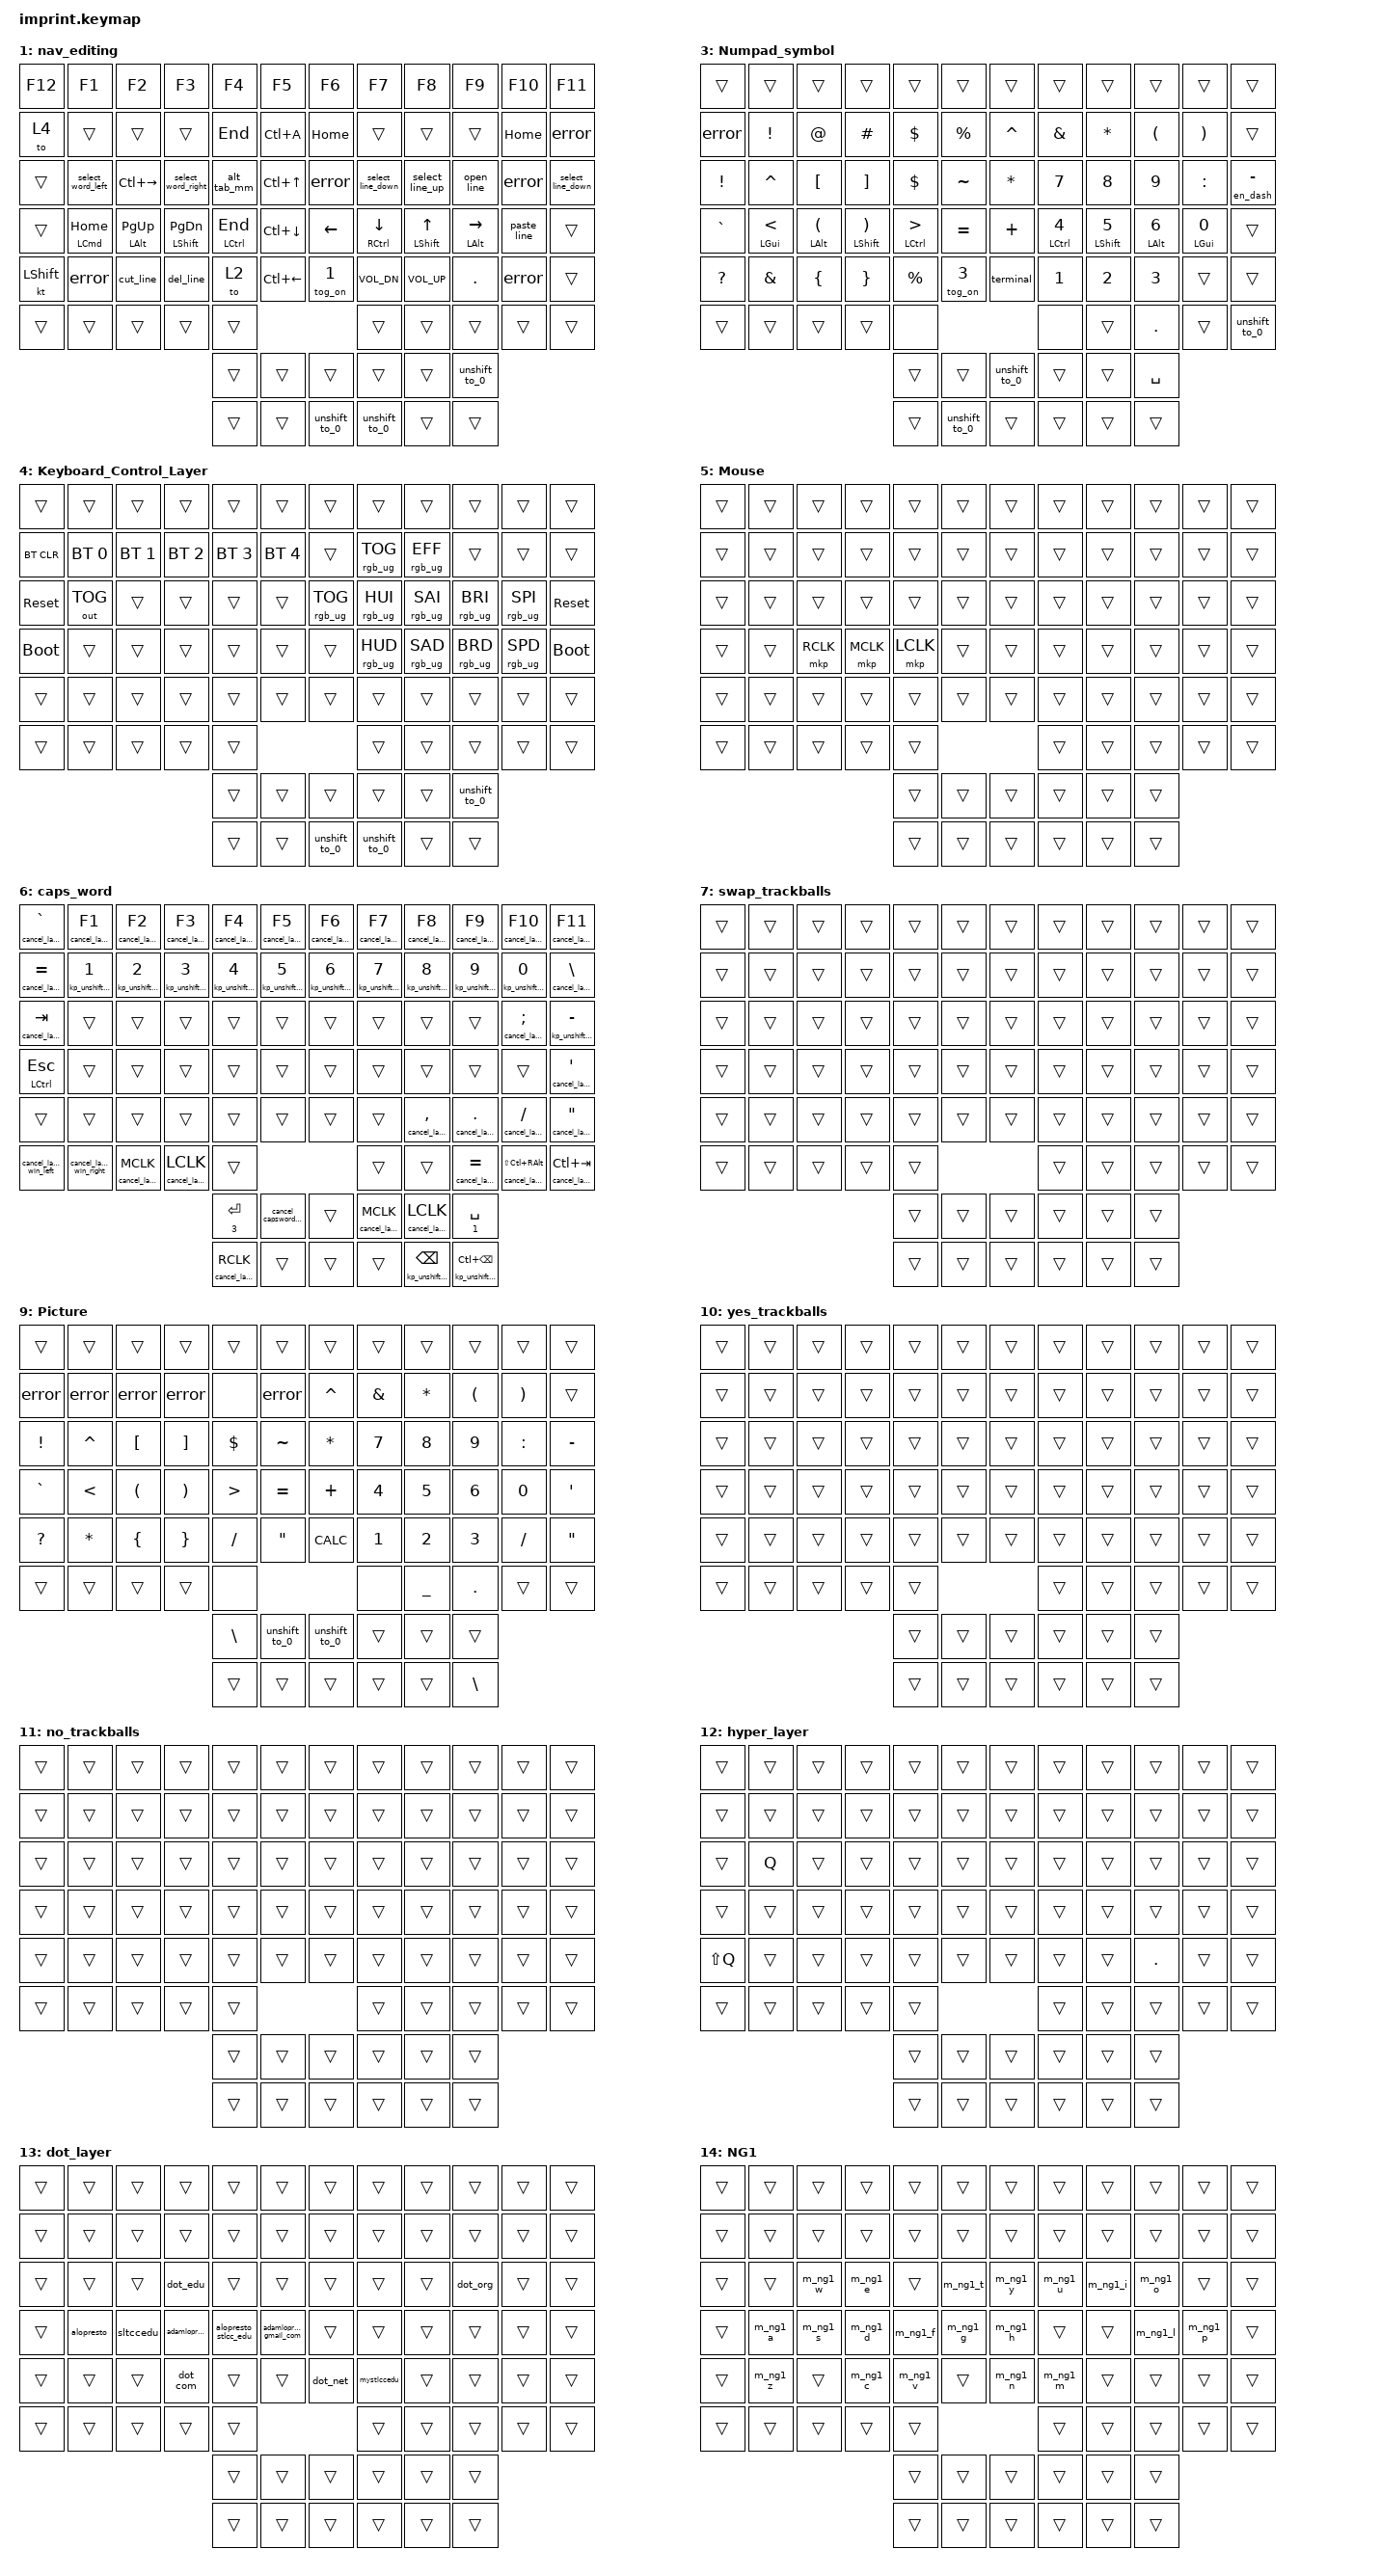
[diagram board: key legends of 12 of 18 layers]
#include <input/processors.dtsi>
#include <zephyr/dt-bindings/input/input-event-codes.h>
#include <dt-bindings/zmk/input_transform.h>
#include <behaviors.dtsi>
#include <dt-bindings/zmk/bt.h>
#include <dt-bindings/zmk/keys.h>
#include <dt-bindings/zmk/outputs.h>
#include <dt-bindings/zmk/pointing.h>
#include <dt-bindings/zmk/rgb.h>

&sk {
    quick-release;
    release-after-ms = <2000>;
};

/ {
    chosen { zmk,physical_layout = &physical_layout_imprint_function_row_full_bottom_row; };

    layer_listeners {
        compatible = "zmk,layer-listeners";

        cancel_mouse_scroll {
            layers = <11>;
            bindings = <&tog_off 10 &none>;
        };

        hyper_with_layer {
            layers = <12>;
            bindings = <&kt_on K_APP &kt_off K_APP>;
        };
    };

    behaviors {
        shift_dance: shift_dance {
            compatible = "zmk,behavior-tap-dance";
            label = "SHIFT_DANCE";
            #binding-cells = <0>;
            bindings = <&sticky_shift_cancel>, <&caps_layer>;
        };

        kt_off: key_toggle_off_only {
            compatible = "zmk,behavior-key-toggle";
            #binding-cells = <1>;
            display-name = "Key Toggle Off";
            toggle-mode = "off";
        };

        mo_to_blue: behavior_mo_to_blue {
            compatible = "zmk,behavior-hold-tap";
            label = "RGB blue, Hold for mo, tap for to layer";
            bindings = <&rgb_layer_mo_blue>, <&rgb_layer_to_blue>;

            #binding-cells = <2>;
            tapping-term-ms = <200>;
            hold-while-undecided;
        };

        hml: homerow_mod_left {
            compatible = "zmk,behavior-hold-tap";
            label = "Homerow mod left";
            bindings = <&kp>, <&kp>;

            #binding-cells = <2>;
            flavor = "balanced";
            tapping-term-ms = <280>;
            quick-tap-ms = <175>;
            require-prior-idle-ms = <250>;
            hold-trigger-on-release;
            hold-trigger-key-positions = <70 71 72 78 77 76 65 73 74 75 79 80 81 6 7 8 9 10 11 18 19 20 21 22 23 30 31 32 33 34 35 42 43 44 45 46 47 54 55 56 57 58 59 65 66 67 68 69>;
        };

        hmr: homerow_mod_right {
            compatible = "zmk,behavior-hold-tap";
            label = "homerow mod right";
            bindings = <&kp>, <&kp>;

            #binding-cells = <2>;
            flavor = "balanced";
            tapping-term-ms = <280>;
            quick-tap-ms = <175>;
            require-prior-idle-ms = <250>;
            hold-trigger-on-release;
            hold-trigger-key-positions = <0 1 2 3 4 5 12 13 14 15 16 17 24 25 26 27 28 29 36 37 38 39 40 41 48 49 50 51 52 53 60 61 62 63 64 70 71 72 73 74 76 77 78 79 80 75 81>;
        };

        hml_new_sentence: homerow_mod_left_ns {
            compatible = "zmk,behavior-hold-tap";
            label = "Homerow mod left ns";
            bindings = <&cancel_layer_kp>, <&sentence_start_kp>;

            #binding-cells = <2>;
            flavor = "balanced";
            tapping-term-ms = <280>;
            quick-tap-ms = <175>;
            require-prior-idle-ms = <250>;
            hold-trigger-on-release;
            hold-trigger-key-positions = <70 71 72 78 77 76 65 73 74 75 79 80 81 6 7 8 9 10 11 18 19 20 21 22 23 30 31 32 33 34 35 42 43 44 45 46 47 54 55 56 57 58 59 65 66 67 68 69>;
        };

        hmr_new_sentence: homerow_mod_right_ns {
            compatible = "zmk,behavior-hold-tap";
            label = "homerow mod right ns";
            bindings = <&cancel_layer_kp>, <&sentence_start_kp>;

            #binding-cells = <2>;
            flavor = "balanced";
            tapping-term-ms = <280>;
            quick-tap-ms = <175>;
            require-prior-idle-ms = <250>;
            hold-trigger-on-release;
            hold-trigger-key-positions = <0 1 2 3 4 5 12 13 14 15 16 17 24 25 26 27 28 29 36 37 38 39 40 41 48 49 50 51 52 53 60 61 62 63 64 70 71 72 73 74 76 77 78 79 80 75 81>;
        };

        tog_on: tog_on {
            compatible = "zmk,behavior-toggle-layer";
            label = "Turn on layer";
            #binding-cells = <1>;

            // locking;
        };

        hyper_tapdance: hyper_tapdance {
            compatible = "zmk,behavior-tap-dance";
            label = "HYPER_TAPDANCE";
            #binding-cells = <0>;
            bindings = <&sl 12>, <&kp F14>;
        };

        win_left: win_left {
            compatible = "zmk,behavior-mod-morph";
            label = "WIN_LEFT";
            bindings = <&kp LS(LG(LEFT))>, <&kp LG(LEFT)>;

            #binding-cells = <0>;
            mods = <(MOD_LCTL|MOD_LSFT|MOD_RCTL|MOD_RSFT)>;
            keep-mods = <(MOD_LCTL|MOD_RCTL)>;
        };

        win_right: win_right {
            compatible = "zmk,behavior-mod-morph";
            label = "WIN_RIGHT";
            bindings = <&kp LG(LS(RIGHT))>, <&kp LG(RIGHT)>;

            #binding-cells = <0>;
            mods = <(MOD_LCTL|MOD_LSFT|MOD_RSFT|MOD_RCTL)>;
            keep-mods = <(MOD_LCTL|MOD_RCTL)>;
        };

        ctrl_esc: ctrl_esc {
            compatible = "zmk,behavior-hold-tap";
            label = "CTRL_ESC";
            bindings = <&kp>, <&cancel_layer_kp>;

            #binding-cells = <2>;
            tapping-term-ms = <250>;
        };

        kt_on: kt_on {
            compatible = "zmk,behavior-key-toggle";
            #binding-cells = <1>;
            display-name = "Key Toggle Off";
            toggle-mode = "on";
            label = "KT_ON";
        };

        sticky_shift_cancel: sticky_shift_cancel {
            compatible = "zmk,behavior-mod-morph";
            label = "STICKY_SHIFT_CANCEL";
            bindings = <&sk LSHIFT>, <&kp K_CANCEL>;

            #binding-cells = <0>;
            mods = <(MOD_LSFT|MOD_RSFT)>;
        };

        tog_off: tog_off {
            compatible = "zmk,behavior-toggle-layer";
            label = "Toggle layer off";
            #binding-cells = <1>;
            toggle-mode = "off";

            // locking;
        };

        open_line: open_line {
            compatible = "zmk,behavior-mod-morph";
            label = "OPEN_LINE";
            bindings = <&open_line_below>, <&open_line_above>;

            #binding-cells = <0>;
            mods = <(MOD_LSFT|MOD_RSFT|MOD_LCTL|MOD_LALT|MOD_LGUI|MOD_RCTL|MOD_RGUI|MOD_RALT)>;
        };

        paste_line: paste_line {
            compatible = "zmk,behavior-mod-morph";
            label = "PASTE_LINE";
            bindings = <&paste_line_below>, <&paste_line_above>;

            #binding-cells = <0>;
            mods = <(MOD_LCTL|MOD_LSFT|MOD_LALT|MOD_LGUI|MOD_RSFT|MOD_RGUI|MOD_RCTL)>;
        };

        alt_tab_mm: alt_tab_mm {
            compatible = "zmk,behavior-mod-morph";
            label = "ALT_TAB_MM";
            bindings = <&alt_tab>, <&kp TAB>;

            #binding-cells = <0>;
            mods = <(MOD_LALT)>;
            keep-mods = <(MOD_LALT|MOD_LSFT)>;
        };

        hyphen_emdash: hyphen_emdash {
            compatible = "zmk,behavior-hold-tap";
            label = "HYPHEN_EMDASH";
            bindings = <&em_dash>, <&always_hyphen>;

            #binding-cells = <2>;
            tapping-term-ms = <150>;
            flavor = "tap-preferred";
            quick-tap-ms = <250>;
            require-prior-idle-ms = <0>;
            hold-trigger-key-positions = <64>;
        };

        hyphen_endash: hyphen_endash {
            compatible = "zmk,behavior-hold-tap";
            label = "HYPHEN_ENDASH";
            bindings = <&en_dash>, <&kp>;

            #binding-cells = <2>;
            tapping-term-ms = <150>;
            flavor = "tap-preferred";
            quick-tap-ms = <250>;
            require-prior-idle-ms = <0>;
            hold-trigger-key-positions = <64>;
        };

        rgb_layer_tap_enter: rgb_layer_tap_enter {
            compatible = "zmk,behavior-hold-tap";
            label = "RGB_LAYER_TAP_ENTER";
            bindings = <&rgb_layer_mo_blue>, <&cancel_layer_kp>;

            #binding-cells = <2>;
            tapping-term-ms = <500>;
            flavor = "hold-preferred";
            require-prior-idle-ms = <0>;
            quick-tap-ms = <200>;
            hold-while-undecided;
        };

        single_quote_ht: single_quote_ht {
            compatible = "zmk,behavior-hold-tap";
            label = "SINGLE_QUOTE_HT";
            bindings = <&single_quotes_pair>, <&kp>;

            #binding-cells = <2>;
            tapping-term-ms = <150>;
            flavor = "tap-preferred";
            quick-tap-ms = <250>;
            require-prior-idle-ms = <0>;
            hold-trigger-key-positions = <70>;
        };

        double_quote_ht: double_quote_ht {
            compatible = "zmk,behavior-hold-tap";
            label = "DOUBLE_QUOTE_HT";
            bindings = <&double_quotes_pair>, <&kp>;

            #binding-cells = <2>;
            tapping-term-ms = <150>;
            flavor = "tap-preferred";
            quick-tap-ms = <250>;
            require-prior-idle-ms = <0>;
            hold-trigger-key-positions = <64>;
        };

        lazy_sk: lazy_sk {
            compatible = "zmk,behavior-sticky-key";
            label = "LAZY_SK";
            bindings = <&kp>;
            #binding-cells = <1>;
            release-after-ms = <2000>;
            lazy;
            quick-release;
        };

        center_mm: center_mm {
            compatible = "zmk,behavior-mod-morph";
            label = "CENTER_MM";
            bindings = <&none>, <&kp F13>;

            #binding-cells = <0>;
            mods = <(MOD_LALT)>;
        };

        hmr_mouse: hmr_mouse {
            compatible = "zmk,behavior-hold-tap";
            label = "hmr_mouse";
            bindings = <&kp>, <&cancel_layer_kp>;

            #binding-cells = <2>;
            flavor = "balanced";
            tapping-term-ms = <280>;
            quick-tap-ms = <175>;
            require-prior-idle-ms = <250>;
            hold-trigger-on-release;
            hold-trigger-key-positions = <0 1 2 3 4 5 12 13 14 15 16 17 24 25 26 27 28 29 36 37 38 39 40 41 48 49 50 51 52 53 60 61 62 63 64 70 71 72 73 74 76 77 78 79 80 75 81>;
        };

        cancel_layer_win_left: cancel_layer_win_left {
            compatible = "zmk,behavior-mod-morph";
            label = "CANCEL_LAYER_WIN_LEFT";
            bindings =
                <&cancel_layer_kp LS(LG(LEFT))>,
                <&cancel_layer_kp LG(LEFT)>;

            #binding-cells = <0>;
            mods = <(MOD_LCTL|MOD_LSFT|MOD_RCTL|MOD_RSFT)>;
            keep-mods = <(MOD_LCTL|MOD_RCTL)>;
        };

        cancel_layer_win_right: cancel_layer_win_right {
            compatible = "zmk,behavior-mod-morph";
            label = "CANCEL_LAYER_WIN_RIGHT";
            bindings =
                <&cancel_layer_kp LG(LS(RIGHT))>,
                <&cancel_layer_kp LG(RIGHT)>;

            #binding-cells = <0>;
            mods = <(MOD_LCTL|MOD_LSFT|MOD_RSFT|MOD_RCTL)>;
            keep-mods = <(MOD_LCTL|MOD_RCTL)>;
        };

        rgb_layer_tap_space: rgb_layer_tap_space {
            compatible = "zmk,behavior-hold-tap";
            label = "RGB_LAYER_TAP_SPACE";
            bindings = <&rgb_layer_mo_blue>, <&cancel_layer_kp>;

            #binding-cells = <2>;
            tapping-term-ms = <500>;
            flavor = "balanced";
            require-prior-idle-ms = <200>;
            quick-tap-ms = <200>;
            hold-while-undecided;
        };

        terminal: terminal {
            compatible = "zmk,behavior-tap-dance";
            label = "TERMINAL";
            #binding-cells = <0>;
            bindings = <&kp LG(GRAVE)>, <&dollar_under>, <&dollar_under_equal>;
        };

        dot: dot {
            compatible = "zmk,behavior-hold-tap";
            label = "DOT";
            bindings = <&mo>, <&kp>;

            #binding-cells = <2>;
            flavor = "balanced";
            tapping-term-ms = <280>;
            quick-tap-ms = <175>;
            require-prior-idle-ms = <250>;
            hold-trigger-key-positions = <38 41 27 51 54 33 32 58 37 39 40>;
        };

        always_hyphen: always_hyphen {
            compatible = "zmk,behavior-mod-morph";
            label = "ALWAYS_HYPHEN";
            bindings = <&kp MINUS>, <&kp_unshifted MINUS>;

            #binding-cells = <0>;
            mods = <(MOD_LSFT|MOD_RSFT)>;
        };

        qu_mm: qu_mm {
            compatible = "zmk,behavior-mod-morph";
            label = "QU_MM";
            bindings = <&qu_macro>, <&qu_caps_macro>;

            #binding-cells = <0>;
            mods = <(MOD_LSFT)>;
        };

        zip_auto_mouse: zip_auto_mouse {
            compatible = "zmk,input-processor-temp-layer";
            #input-processor-cells = <2>;
            require-prior-idle-ms = <1000>;
            excluded-positions = <64>;
        };

        zip_scroll_to_vol: zip_scroll_to_vol {
            compatible = "zmk,input-processor-keybind";
            #input-processor-cells = <0>;
            bindings = <&none>, <&none>, <&kp C_VOL_UP>, <&kp C_VOL_DN>;
        };

        zip_keybind_keys: zip_keybind_keys {
            compatible = "zmk,input-processor-keybind";
            #input-processor-cells = <0>;
            track_remainders;
            bindings = <&kp RIGHT>, <&kp LEFT>, <&kp UP>, <&kp DOWN>;

            tick = <15>;
            wait-ms = <0>;
            tap-ms = <10>;

            // mode = <1>
            // threshold = <10>
            // max_threshold = <200>
            // max_pending_activations = <10>
        };

        // Scoped momentary layer that turns off continuation layers 15 & 17 on thumb release

        ng_hold: ng_hold {
            compatible = "zmk,behavior-macro-one-param";
            label = "NG_HOLD";
            #binding-cells = <1>;
            wait-ms = <0>;
            tap-ms = <0>;
            bindings =
                <&macro_param_1to1>,
                <&macro_press>,
                <&mo MACRO_PLACEHOLDER>,
                <&macro_pause_for_release>,
                <&macro_param_1to1>,
                <&macro_release>,
                <&mo MACRO_PLACEHOLDER>,
                <&macro_tap>,
                <&tog_off 15>,
                <&macro_tap>,
                <&tog_off 17>;
        };

        // Hold-tap for thumb positions 80 and 81

        ng_lt: ng_lt {
            compatible = "zmk,behavior-hold-tap";
            label = "NG_LT";
            bindings = <&ng_hold>, <&kp>;

            #binding-cells = <2>;
            flavor = "hold-preferred";
            tapping-term-ms = <200>;
            quick-tap-ms = <175>;
        };

        alt_f4: alt_f4 {
            compatible = "zmk,behavior-mod-morph";
            label = "ALT_F4";
            bindings = <&kp LA(F4)>, <&kp F4>;

            #binding-cells = <0>;
            mods = <(MOD_LCTL|MOD_LSFT|MOD_LALT|MOD_LGUI)>;
            keep-mods = <(MOD_LCTL|MOD_LSFT|MOD_LGUI)>;
        };

        // zip_auto_scroll: zip_auto_scroll {
        //     compatible = "zmk,input-processor-temp-layer";
        //     #input-processor-cells = <2>;
        //     require-prior-idle-ms = <1000>;
        //     excluded-positions = <64>;
        // };
    };

    macros {
        select_word_left: select_word_left {
            compatible = "zmk,behavior-macro";
            #binding-cells = <0>;
            bindings = <&tog_on 2 &kp LC(LEFT) &kp LC(RIGHT) &kp LS(LC(LEFT))>;
            label = "SELECT_WORD_LEFT";
            wait-ms = <0>;
            tap-ms = <0>;
        };

        select_word_right: select_word_right {
            compatible = "zmk,behavior-macro";
            #binding-cells = <0>;
            bindings = <&tog_on 2 &kp LC(RIGHT) &kp LC(LEFT) &kp LS(LC(RIGHT))>;
            label = "SELECT_WORD_RIGHT";
            wait-ms = <0>;
            tap-ms = <0>;
        };

        select_line_down: select_line_down {
            compatible = "zmk,behavior-macro";
            #binding-cells = <0>;
            bindings = <&tog_on 2 &kp HOME &kp LS(END)>;
            label = "SELECT_LINE";
            wait-ms = <0>;
            tap-ms = <0>;
        };

        select_line_up: select_line_up {
            compatible = "zmk,behavior-macro";
            #binding-cells = <0>;
            bindings = <&tog_on 2 &kp END &kp LS(HOME)>;
            label = "SELECT_LINE_UP";
            wait-ms = <0>;
            tap-ms = <0>;
        };

        unshift_to_0: unshift_to_0 {
            compatible = "zmk,behavior-macro";
            #binding-cells = <0>;
            bindings = <&kt_off LSHIFT &rgb_ug RGB_OFF &rgb_ug RGB_COLOR_HSB(0,0,1) &kt_off LALT &tog_off 1 &tog_off 2 &tog_off 3 &tog_off 4 &tog_off 5 &tog_off 6 &tog_off 7 &tog_off 8 &tog_off 9 &tog_off 10 &tog_off 14 &tog_off 15 &tog_off 16 &tog_off 17>;
            label = "UNSHIFT_TO_0";
            wait-ms = <0>;
            tap-ms = <0>;
        };

        rgb_layer_to_blue: rgb_layer_to {
            compatible = "zmk,behavior-macro-one-param";
            #binding-cells = <1>;
            bindings = <&macro_param_1to1 &to MACRO_PLACEHOLDER &rgb_ug RGB_COLOR_HSB(223,100,1) &rgb_ug RGB_ON>;
            label = "RGB_LAYER_TOG";
            wait-ms = <0>;
            tap-ms = <0>;
        };

        rgb_layer_mo_blue: rgb_layer_mo {
            compatible = "zmk,behavior-macro-one-param";
            #binding-cells = <1>;
            bindings =
                <&unshift_to_0>,
                <&macro_press>,
                <&macro_param_1to1 &mo MACRO_PLACEHOLDER &rgb_ug RGB_COLOR_HSB(199,100,1) &rgb_ug RGB_ON>,
                <&macro_pause_for_release>,
                <&macro_release>,
                <&macro_param_1to1 &mo MACRO_PLACEHOLDER>,
                <&macro_tap>,
                <&rgb_ug RGB_OFF &rgb_ug RGB_COLOR_HSB(0,0,1) &center_mm &kt_off LEFT_ALT &tog_off 2>;

            label = "RGB_LAYER_MO";
            wait-ms = <0>;
            tap-ms = <0>;
        };

        rgb_layer_to_green: rgb_layer_tog_green {
            compatible = "zmk,behavior-macro-one-param";
            #binding-cells = <1>;
            bindings = <&macro_param_1to1 &to MACRO_PLACEHOLDER &rgb_ug RGB_COLOR_HSB(116,100,1) &rgb_ug RGB_ON>;
            label = "RGB_LAYER_TOG_GREEN";
            wait-ms = <0>;
            tap-ms = <0>;
        };

        rgb_layer_to_yellow: rgb_layer_to_yellow {
            compatible = "zmk,behavior-macro-one-param";
            #binding-cells = <1>;
            bindings = <&macro_param_1to1 &to MACRO_PLACEHOLDER &rgb_ug RGB_COLOR_HSB(61,85,1) &rgb_ug RGB_ON>;
            label = "RGB_LAYER_TO_YELLOW";
            wait-ms = <0>;
            tap-ms = <0>;
        };

        hyper_kp: hyper_kp {
            compatible = "zmk,behavior-macro-one-param";
            #binding-cells = <1>;
            bindings = <&sk K_APP &macro_param_1to1 &kp MACRO_PLACEHOLDER>;
            label = "HYPER_KP";
        };

        kp_unshifted: kp_unshifted {
            compatible = "zmk,behavior-macro-one-param";
            #binding-cells = <1>;
            bindings = <&kt_off LSHIFT &macro_param_1to1 &kp MACRO_PLACEHOLDER &kt LSHIFT>;
            label = "KP_UNSHIFTED";
            wait-ms = <0>;
            tap-ms = <0>;
        };

        cancel_layer_kp: cancel_layer_kp {
            compatible = "zmk,behavior-macro-one-param";
            #binding-cells = <1>;
            bindings =
                <&unshift_to_0>,
                <&macro_press>,
                <&macro_param_1to1 &kp MACRO_PLACEHOLDER>,
                <&macro_pause_for_release>,
                <&macro_release>,
                <&macro_param_1to1 &kp MACRO_PLACEHOLDER>;

            label = "CANCEL_LAYER_KP";
            wait-ms = <0>;
            tap-ms = <0>;
        };

        caps_layer: caps_layer {
            compatible = "zmk,behavior-macro";
            #binding-cells = <0>;
            bindings = <&to 6 &kt LSHIFT &rgb_ug RGB_COLOR_HSB(0,0,1) &rgb_ug RGB_ON>;
            label = "CAPS_LAYER";
            wait-ms = <0>;
            tap-ms = <0>;
        };

        cancel_layer_mkp: cancel_capsword_mp {
            compatible = "zmk,behavior-macro-one-param";
            #binding-cells = <1>;
            bindings =
                <&unshift_to_0>,
                <&macro_press>,
                <&macro_param_1to1 &mkp MACRO_PLACEHOLDER>,
                <&macro_pause_for_release>,
                <&macro_release>,
                <&macro_param_1to1 &mkp MACRO_PLACEHOLDER>;

            label = "CANCEL_CAPSWORD_MP";
            wait-ms = <0>;
            tap-ms = <0>;
        };

        cancel_capsword_shift: cancel_capsword_shift {
            compatible = "zmk,behavior-macro";
            #binding-cells = <0>;
            bindings =
                <&unshift_to_0 &kt LSHIFT>,
                <&macro_pause_for_release>,
                <&kt LEFT_SHIFT>;

            label = "CANCEL_CAPSWORD_SHIFT";
        };

        error: error {
            compatible = "zmk,behavior-macro";
            #binding-cells = <0>;
            bindings =
                <&kp F14 &rgb_ug RGB_TOG>,
                <&macro_wait_time 125>,
                <&rgb_ug RGB_TOG>;

            label = "ERROR";
        };

        rgb_layer_mo_green: rgb_layer_mo_green {
            compatible = "zmk,behavior-macro-one-param";
            #binding-cells = <1>;
            bindings =
                <&unshift_to_0>,
                <&macro_press>,
                <&macro_param_1to1 &mo MACRO_PLACEHOLDER &rgb_ug RGB_COLOR_HSB(124,100,1) &rgb_ug RGB_ON>,
                <&macro_pause_for_release>,
                <&macro_release>,
                <&macro_param_1to1 &mo MACRO_PLACEHOLDER>,
                <&macro_tap>,
                <&rgb_ug RGB_OFF &rgb_ug RGB_COLOR_HSB(0,0,1)>;

            label = "RGB_LAYER_MO_GREEN";
            wait-ms = <0>;
            tap-ms = <0>;
        };

        drag_toggle: drag_toggle {
            compatible = "zmk,behavior-macro";
            #binding-cells = <0>;
            bindings = <&macro_release>, <&mkp MB1>, <&macro_press>, <&mkp MB1>;

            label = "DRAG_TOGGLE";
        };

        unclick_click: unclick_click {
            compatible = "zmk,behavior-macro";
            #binding-cells = <0>;
            bindings =
                <&macro_release>,
                <&mkp MB1>,
                <&macro_press>,
                <&mkp MB1>,
                <&macro_pause_for_release>,
                <&macro_release>,
                <&mkp MB1>;

            label = "UNCLICK_CLICK";
            wait-ms = <0>;
            tap-ms = <0>;
        };

        alt_tab: alt_tab {
            compatible = "zmk,behavior-macro";
            #binding-cells = <0>;
            bindings = <&kt_on LALT &kp TAB>;
            label = "ALT_TAB";
        };

        pair_macro: pair_macro {
            compatible = "zmk,behavior-macro-two-param";
            #binding-cells = <2>;
            bindings = <&macro_param_1to1 &kp MACRO_PLACEHOLDER &macro_param_2to1 &kp MACRO_PLACEHOLDER &kp LEFT>;
            label = "PAIR_MACRO";
        };

        error_kp: error_kp {
            compatible = "zmk,behavior-macro-one-param";
            #binding-cells = <1>;
            bindings = <&macro_param_1to1 &kp MACRO_PLACEHOLDER &error>;
            label = "ERROR_KP";
        };

        sentence_end: sentence_end {
            compatible = "zmk,behavior-macro-one-param";
            #binding-cells = <1>;
            bindings = <&kt_off LSHIFT &macro_param_1to1 &kp MACRO_PLACEHOLDER &tog_on 8 &rgb_ug RGB_COLOR_HSB(0,0,1) &rgb_ug RGB_ON>;
            label = "SENTENCE_END";
            wait-ms = <0>;
            tap-ms = <0>;
        };

        sentence_start_kp: sentence_start {
            compatible = "zmk,behavior-macro-one-param";
            #binding-cells = <1>;
            bindings =
                <&unshift_to_0 &kp SPACE>,
                <&macro_press>,
                <&macro_param_1to1 &kp MACRO_PLACEHOLDER>,
                <&macro_pause_for_release>,
                <&macro_release>,
                <&macro_param_1to1 &kp MACRO_PLACEHOLDER &unshift_to_0>;

            label = "Send space then kp";
            wait-ms = <0>;
            tap-ms = <0>;
        };

        cut_line: cut_line {
            compatible = "zmk,behavior-macro";
            #binding-cells = <0>;
            bindings = <&kp HOME &kp LS(END) &kp LC(X) &kp DELETE>;
            label = "CUT_LINE";
            wait-ms = <0>;
            tap-ms = <0>;
        };

        open_line_above: open_line_above {
            compatible = "zmk,behavior-macro";
            #binding-cells = <0>;
            bindings = <&kp HOME &kt_off LSHIFT &kp ENTER &kt_off LSHIFT &kp UP>;
            label = "OPEN_LINE_ABOVE";
            wait-ms = <0>;
            tap-ms = <0>;
        };

        open_line_below: open_line_below {
            compatible = "zmk,behavior-macro";
            #binding-cells = <0>;
            bindings = <&kp END &kp ENTER>;
            label = "OPEN_LINE_BELOW";
            wait-ms = <0>;
            tap-ms = <0>;
        };

        paste_line_above: paste_line_above {
            compatible = "zmk,behavior-macro";
            #binding-cells = <0>;
            bindings = <&kp HOME &kt_off LSHIFT &kp ENTER &kt_off LSHIFT &kp UP &kt_off LSHIFT &kp LC(V)>;
            label = "PASTE_LINE_ABOVE";
            wait-ms = <0>;
            tap-ms = <0>;
        };

        paste_line_below: paste_line_below {
            compatible = "zmk,behavior-macro";
            #binding-cells = <0>;
            bindings = <&kp END &kp ENTER &kp LC(V)>;
            label = "PASTE_LINE_BELOW";
            wait-ms = <0>;
            tap-ms = <0>;
        };

        paste_replace: paste_replace {
            compatible = "zmk,behavior-macro";
            #binding-cells = <0>;
            bindings =
                <&kt_off LSHIFT &kp LC(X) &kp LG(V)>,
                <&macro_wait_time 1000>,
                <&kp DOWN &kp ENTER>;

            label = "PASTE_REPLACE";
        };

        del_line: del_line {
            compatible = "zmk,behavior-macro";
            #binding-cells = <0>;
            bindings = <&kp HOME &kp LS(END) &kp DELETE &kp DELETE>;
            label = "DEL_LINE";
            wait-ms = <0>;
            tap-ms = <0>;
        };

        en_dash: en_dash {
            compatible = "zmk,behavior-macro";
            #binding-cells = <0>;
            bindings = <&kp LG(MINUS)>;
            label = "EN_DASH";
            wait-ms = <0>;
            tap-ms = <0>;
        };

        em_dash: em_dash {
            compatible = "zmk,behavior-macro";
            #binding-cells = <0>;
            bindings = <&kp LS(LG(MINUS))>;
            label = "EM_DASH";
            wait-ms = <0>;
            tap-ms = <0>;
        };

        double_quotes_pair: double_quotes_pair {
            compatible = "zmk,behavior-macro";
            #binding-cells = <0>;
            bindings = <&kp RA(GRAVE) &kp GRAVE &kp RA(SINGLE_QUOTE) &kp SINGLE_QUOTE &kp LEFT>;
            label = "DOUBLE_QUOTES_PAIR";
        };

        single_quotes_pair: single_quotes_pair {
            compatible = "zmk,behavior-macro";
            #binding-cells = <0>;
            bindings = <&kp RA(N6) &kp SINGLE_QUOTE &kp RA(N9) &kp SINGLE_QUOTE &kp LEFT>;
            label = "SINGLE_QUOTES_PAIR";
        };

        the_macro: the_macro {
            compatible = "zmk,behavior-macro";
            #binding-cells = <0>;
            bindings = <&kp T &kp H &kp E>;
            label = "THE_MACRO";
            tap-ms = <0>;
            wait-ms = <0>;
        };

        the_caps_macro: the_caps_macro {
            compatible = "zmk,behavior-macro";
            #binding-cells = <0>;
            bindings = <&kp LS(T) &kt_off LSHFT &kp H &kp E>;
            label = "THE_CAPS_MACRO";
            wait-ms = <0>;
            tap-ms = <0>;
        };

        sentence_start_the_macro: sentence_start_the_macro {
            compatible = "zmk,behavior-macro";
            #binding-cells = <0>;
            bindings = <&unshift_to_0 &kp SPACE &kp LS(T) &kp H &kp E>;
            label = "SENTENCE_START_THE_MACRO";
            wait-ms = <0>;
            tap-ms = <0>;
        };

        double_click: double_click {
            compatible = "zmk,behavior-macro-one-param";
            #binding-cells = <1>;
            bindings =
                <&unshift_to_0 &macro_param_1to1 &mkp MACRO_PLACEHOLDER>,
                <&macro_press>,
                <&macro_param_1to1 &mkp MACRO_PLACEHOLDER>,
                <&macro_pause_for_release>,
                <&macro_release>,
                <&macro_param_1to1 &mkp MACRO_PLACEHOLDER>;

            label = "DOUBLE_CLICK";
        };

        tion_macro: tion_macro {
            compatible = "zmk,behavior-macro";
            #binding-cells = <0>;
            bindings = <&kp T &kp I &kp O &kp N>;
            label = "TION_MACRO";
            wait-ms = <0>;
            tap-ms = <0>;
        };

        ing_macro: ing_macro {
            compatible = "zmk,behavior-macro";
            #binding-cells = <0>;
            bindings = <&kp I &kp N &kp G>;
            label = "ING_MACRO";
            wait-ms = <0>;
            tap-ms = <0>;
        };

        rgb_on: rgb_on {
            compatible = "zmk,behavior-macro";
            #binding-cells = <0>;
            bindings = <&rgb_ug RGB_COLOR_HSB(0,100,0) &rgb_ug RGB_ON>;
            label = "RGB_ON";
        };

        cancel_trackball_mkp: cancel_trackball_mkp {
            compatible = "zmk,behavior-macro-one-param";
            #binding-cells = <1>;
            bindings =
                <&macro_press>,
                <&macro_param_1to1 &mkp MACRO_PLACEHOLDER>,
                <&macro_pause_for_release>,
                <&macro_release>,
                <&macro_param_1to1 &mkp MACRO_PLACEHOLDER>,
                <&macro_tap>,
                <&tog_off 10 &sl 10>;

            label = "CANCEL_TRACKBALL_MKP";
            wait-ms = <0>;
            tap-ms = <0>;
        };

        ough_macro: ought_macro {
            compatible = "zmk,behavior-macro";
            #binding-cells = <0>;
            bindings = <&kp O &kp U &kp G &kp H>;
            label = "OUGHT_MACRO";
            wait-ms = <10>;
            tap-ms = <15>;
        };

        qu_macro: qu_macro {
            compatible = "zmk,behavior-macro";
            #binding-cells = <0>;
            bindings = <&kp Q &kp U>;
            label = "QU_MACRO";
            wait-ms = <0>;
            tap-ms = <0>;
        };

        qu_macro_sentence_start: qu_macro_sentence_start {
            compatible = "zmk,behavior-macro";
            #binding-cells = <0>;
            bindings = <&unshift_to_0 &kp SPACE &kp LS(Q) &kp U>;
            label = "QU_MACRO_SENTENCE_START";
            wait-ms = <0>;
            tap-ms = <0>;
        };

        hyper_hold: hyper_macro {
            compatible = "zmk,behavior-macro";
            #binding-cells = <0>;
            bindings =
                <&macro_press>,
                <&mo 12 &kp K_APP>,
                <&macro_pause_for_release>,
                <&macro_release>,
                <&mo 12 &kp K_APP>;

            label = "HYPER_MACRO";
            wait-ms = <0>;
            tap-ms = <0>;
        };

        surround: surround {
            compatible = "zmk,behavior-macro-two-param";
            #binding-cells = <2>;
            bindings = <&kp LC(X) &macro_param_1to1 &kp MACRO_PLACEHOLDER &kp LC(V) &macro_param_2to1 &kp MACRO_PLACEHOLDER>;
            label = "SURROUND";
        };

        dollar_under: dollar_under {
            compatible = "zmk,behavior-macro";
            #binding-cells = <0>;
            bindings = <&kp DLLR &kp UNDER &kp UNDER>;
            label = "DOLLAR_UNDER";
        };

        dollar_under_equal: dollar_under_equal {
            compatible = "zmk,behavior-macro";
            #binding-cells = <0>;
            bindings = <&kp DLLR &kp UNDER &kp UNDER &kp EQUAL>;
            label = "DOLLAR_UNDER_EQUAL";
        };

        thanks_macro: thanks_macro {
            compatible = "zmk,behavior-macro";
            #binding-cells = <0>;
            bindings = <&kp LS(T) &kp H &kp A &kp N &kp K &kp S &sentence_end EXCLAMATION>;
            label = "THANKS_MACRO";
            wait-ms = <0>;
            tap-ms = <0>;
        };

        and_macro: and_macro {
            compatible = "zmk,behavior-macro";
            #binding-cells = <0>;
            bindings = <&kp SPACE &kp A &kp N &kp D &kp SPACE>;
            label = "AND_MACRO";
            wait-ms = <0>;
            tap-ms = <0>;
        };

        dot_com: dot_com {
            compatible = "zmk,behavior-macro";
            #binding-cells = <0>;
            bindings = <&kp DOT &kp C &kp O &kp M>;
            label = "DOT_COM";
            wait-ms = <0>;
            tap-ms = <0>;
        };

        dot_net: dot_net {
            compatible = "zmk,behavior-macro";
            #binding-cells = <0>;
            bindings = <&kp DOT &kp N &kp E &kp T>;
            label = "DOT_NET";
            wait-ms = <0>;
            tap-ms = <0>;
        };

        dot_org: dot_org {
            compatible = "zmk,behavior-macro";
            #binding-cells = <0>;
            bindings = <&kp DOT &kp O &kp R &kp G>;
            label = "DOT_ORG";
            wait-ms = <0>;
            tap-ms = <0>;
        };

        dot_edu: dot_edu {
            compatible = "zmk,behavior-macro";
            #binding-cells = <0>;
            bindings = <&kp DOT &kp E &kp D &kp U>;
            label = "DOT_EDU";
            wait-ms = <0>;
            tap-ms = <0>;
        };

        alopresto_stlcc_edu: alopresto_stlcc_edu {
            compatible = "zmk,behavior-macro";
            #binding-cells = <0>;
            bindings = <&kp A &kp L &kp O &kp P &kp R &kp E &kp S &kp T &kp O &kp AT &kp S &kp T &kp L &kp C &kp C &kp DOT &kp E &kp D &kp U>;
            label = "ALOPRESTO_STLCC_EDU";
        };

        adamlopresto_gmail_com: adamlopresto_gmail_com {
            compatible = "zmk,behavior-macro";
            #binding-cells = <0>;
            bindings = <&kp A &kp D &kp A &kp M &kp L &kp O &kp P &kp R &kp E &kp S &kp T &kp O &kp AT &kp G &kp M &kp A &kp I &kp L &kp DOT &kp C &kp O &kp M>;
            label = "ADAMLOPRESTO_GMAIL_COM";
        };

        qu_caps_macro: qu_caps_macro {
            compatible = "zmk,behavior-macro";
            #binding-cells = <0>;
            bindings = <&kp LS(Q) &kp U>;
            label = "QU_CAPS_MACRO";
            wait-ms = <0>;
            tap-ms = <0>;
        };

        adamlopresto: adamlopresto {
            compatible = "zmk,behavior-macro";
            #binding-cells = <0>;
            bindings = <&kp A &kp D &kp A &kp M &kp L &kp O &kp P &kp R &kp E &kp S &kp T &kp O>;
            label = "ADAMLOPRESTO";
        };

        alopresto: alopresto {
            compatible = "zmk,behavior-macro";
            #binding-cells = <0>;
            bindings = <&kp A &kp L &kp O &kp P &kp R &kp E &kp S &kp T &kp O>;
            label = "ALOPRESTO";
        };

        sltccedu: sltccedu {
            compatible = "zmk,behavior-macro";
            #binding-cells = <0>;
            bindings = <&kp S &kp T &kp L &kp C &kp C &kp DOT &kp E &kp D &kp U>;
            label = "SLTCCEDU";
        };

        mystlccedu: mystlccedu {
            compatible = "zmk,behavior-macro";
            #binding-cells = <0>;
            bindings = <&kp AT &kp M &kp Y &kp DOT &kp S &kp T &kp L &kp C &kp C &kp DOT &kp E &kp D &kp U>;
            label = "MYSTLCCEDU";
        };

        /* =========================================================================
         * NGRAM1 (Layer 14) & NGRAM1_CON (Layer 15) - Hold Key Pos 81
         * ========================================================================= */

        m_ng1_a: m_ng1_a {
            compatible = "zmk,behavior-macro";
            #binding-cells = <0>;
            wait-ms = <5>;
            tap-ms = <5>;
            bindings = <&kp A &kp B &kp L &kp E>, <&macro_tap>, <&tog_on 15>;

            // able
        };

        m_ng1con_a: m_ng1con_a {
            compatible = "zmk,behavior-macro";
            #binding-cells = <0>;
            wait-ms = <5>;
            tap-ms = <5>;
            bindings = <&kp BSPC &kp Y>, <&macro_tap>, <&tog_off 15>;

            // ably
        };

        m_ng1_c: m_ng1_c {
            compatible = "zmk,behavior-macro";
            #binding-cells = <0>;
            wait-ms = <5>;
            tap-ms = <5>;
            bindings = <&kp C &kp O &kp N>, <&macro_tap>, <&tog_on 15>;

            // con
        };

        m_ng1con_c: m_ng1con_c {
            compatible = "zmk,behavior-macro";
            #binding-cells = <0>;
            wait-ms = <5>;
            tap-ms = <5>;
            bindings =
                <&kp T &kp I &kp N &kp U &kp E>,
                <&macro_tap>,
                <&tog_off 15>;

            // continue
        };

        m_ng1_d: m_ng1_d {
            compatible = "zmk,behavior-macro";
            #binding-cells = <0>;
            wait-ms = <5>;
            tap-ms = <5>;
            bindings = <&kp O &kp U &kp L &kp D>, <&macro_tap>, <&tog_on 15>;

            // ould
        };

        m_ng1con_d: m_ng1con_d {
            compatible = "zmk,behavior-macro";
            #binding-cells = <0>;
            wait-ms = <5>;
            tap-ms = <5>;
            bindings = <&kp N &kp SQT &kp T>, <&macro_tap>, <&tog_off 15>;

            // ouldn't
        };

        m_ng1_e: m_ng1_e {
            compatible = "zmk,behavior-macro";
            #binding-cells = <0>;
            wait-ms = <5>;
            tap-ms = <5>;
            bindings = <&kp E &kp V &kp E &kp R>, <&macro_tap>, <&tog_on 15>;

            // ever
        };

        m_ng1con_e: m_ng1con_e {
            compatible = "zmk,behavior-macro";
            #binding-cells = <0>;
            wait-ms = <5>;
            tap-ms = <5>;
            bindings = <&kp Y>, <&macro_tap>, <&tog_off 15>;

            // every
        };

        m_ng1_f: m_ng1_f {
            compatible = "zmk,behavior-macro";
            #binding-cells = <0>;
            wait-ms = <5>;
            tap-ms = <5>;
            bindings = <&kp F &kp U &kp L>, <&macro_tap>, <&tog_on 15>;

            // ful
        };

        m_ng1con_f: m_ng1con_f {
            compatible = "zmk,behavior-macro";
            #binding-cells = <0>;
            wait-ms = <5>;
            tap-ms = <5>;
            bindings = <&kp L &kp Y>, <&macro_tap>, <&tog_off 15>;

            // fully
        };

        m_ng1_g: m_ng1_g {
            compatible = "zmk,behavior-macro";
            #binding-cells = <0>;
            wait-ms = <5>;
            tap-ms = <5>;
            bindings = <&kp A &kp G &kp E>, <&macro_tap>, <&tog_on 15>;

            // age
        };

        m_ng1con_g: m_ng1con_g {
            compatible = "zmk,behavior-macro";
            #binding-cells = <0>;
            wait-ms = <5>;
            tap-ms = <5>;
            bindings = <&kp S>, <&macro_tap>, <&tog_off 15>;

            // ages
        };

        m_ng1_h: m_ng1_h {
            compatible = "zmk,behavior-macro";
            #binding-cells = <0>;
            wait-ms = <5>;
            tap-ms = <5>;
            bindings = <&kp H &kp A &kp V &kp E>, <&macro_tap>, <&tog_on 15>;

            // have
        };

        m_ng1con_h: m_ng1con_h {
            compatible = "zmk,behavior-macro";
            #binding-cells = <0>;
            wait-ms = <5>;
            tap-ms = <5>;
            bindings = <&kp N &kp SQT &kp T>, <&macro_tap>, <&tog_off 15>;

            // haven't
        };

        m_ng1_i: m_ng1_i {
            compatible = "zmk,behavior-macro";
            #binding-cells = <0>;
            wait-ms = <5>;
            tap-ms = <5>;
            bindings = <&kp I &kp G &kp H &kp T>, <&macro_tap>, <&tog_on 15>;

            // ight
        };

        m_ng1con_i: m_ng1con_i {
            compatible = "zmk,behavior-macro";
            #binding-cells = <0>;
            wait-ms = <5>;
            tap-ms = <5>;
            bindings = <&kp S>, <&macro_tap>, <&tog_off 15>;

            // ights
        };

        m_ng1_l: m_ng1_l {
            compatible = "zmk,behavior-macro";
            #binding-cells = <0>;
            wait-ms = <5>;
            tap-ms = <5>;
            bindings =
                <&kp A &kp L &kp L &kp Y &kp SPACE>,
                <&macro_tap>,
                <&tog_on 15>;

            // ally
        };

        m_ng1con_l: m_ng1con_l {
            compatible = "zmk,behavior-macro";
            #binding-cells = <0>;
            wait-ms = <5>;
            tap-ms = <5>;
            bindings =
                <&kp BSPC &kp BSPC &kp BSPC &kp BSPC &kp BACKSPACE &kp I &kp C &kp A &kp L &kp L &kp Y &kp SPACE>,
                <&macro_tap>,
                <&tog_off 15>;

            // ically
        };

        m_ng1_m: m_ng1_m {
            compatible = "zmk,behavior-macro";
            #binding-cells = <0>;
            wait-ms = <5>;
            tap-ms = <5>;
            bindings = <&kp M &kp E &kp N &kp T>, <&macro_tap>, <&tog_on 15>;

            // ment
        };

        m_ng1con_m: m_ng1con_m {
            compatible = "zmk,behavior-macro";
            #binding-cells = <0>;
            wait-ms = <5>;
            tap-ms = <5>;
            bindings = <&kp S>, <&macro_tap>, <&tog_off 15>;

            // ments
        };

        m_ng1_n: m_ng1_n {
            compatible = "zmk,behavior-macro";
            #binding-cells = <0>;
            wait-ms = <5>;
            tap-ms = <5>;
            bindings = <&kp N &kp E &kp S &kp S>, <&macro_tap>, <&tog_on 15>;

            // ness
        };

        m_ng1con_n: m_ng1con_n {
            compatible = "zmk,behavior-macro";
            #binding-cells = <0>;
            wait-ms = <5>;
            tap-ms = <5>;
            bindings = <&kp E &kp S &kp SPACE>, <&macro_tap>, <&tog_off 15>;

            // nesses
        };

        m_ng1_o: m_ng1_o {
            compatible = "zmk,behavior-macro";
            #binding-cells = <0>;
            wait-ms = <5>;
            tap-ms = <5>;
            bindings = <&kp O &kp U &kp S>, <&macro_tap>, <&tog_on 15>;

            // ous
        };

        m_ng1con_o: m_ng1con_o {
            compatible = "zmk,behavior-macro";
            #binding-cells = <0>;
            wait-ms = <5>;
            tap-ms = <5>;
            bindings = <&kp L &kp Y &kp SPACE>, <&macro_tap>, <&tog_off 15>;

            // ously
        };

        m_ng1_p: m_ng1_p {
            compatible = "zmk,behavior-macro";
            #binding-cells = <0>;
            wait-ms = <5>;
            tap-ms = <5>;
            bindings = <&kp P &kp R &kp O>, <&macro_tap>, <&tog_on 15>;

            // pro
        };

        m_ng1con_p: m_ng1con_p {
            compatible = "zmk,behavior-macro";
            #binding-cells = <0>;
            wait-ms = <5>;
            tap-ms = <5>;
            bindings =
                <&kp B &kp A &kp B &kp L &kp Y &kp SPACE>,
                <&macro_tap>,
                <&tog_off 15>;

            // probably
        };

        m_ng1_s: m_ng1_s {
            compatible = "zmk,behavior-macro";
            #binding-cells = <0>;
            wait-ms = <5>;
            tap-ms = <5>;
            bindings = <&kp S &kp I &kp O &kp N>, <&macro_tap>, <&tog_on 15>;

            // sion
        };

        m_ng1con_s: m_ng1con_s {
            compatible = "zmk,behavior-macro";
            #binding-cells = <0>;
            wait-ms = <5>;
            tap-ms = <5>;
            bindings = <&kp S &kp SPACE>, <&macro_tap>, <&tog_off 15>;

            // sions
        };

        m_ng1_t: m_ng1_t {
            compatible = "zmk,behavior-macro";
            #binding-cells = <0>;
            wait-ms = <5>;
            tap-ms = <5>;
            bindings = <&kp T &kp H &kp A &kp T>, <&macro_tap>, <&tog_on 15>;

            // that
        };

        m_ng1con_t: m_ng1con_t {
            compatible = "zmk,behavior-macro";
            #binding-cells = <0>;
            wait-ms = <5>;
            tap-ms = <5>;
            bindings = <&kp BSPC &kp N>, <&macro_tap>, <&tog_off 15>;

            // than
        };

        m_ng1_u: m_ng1_u {
            compatible = "zmk,behavior-macro";
            #binding-cells = <0>;
            wait-ms = <5>;
            tap-ms = <5>;
            bindings = <&kp U &kp R &kp E>, <&macro_tap>, <&tog_on 15>;

            // ure
        };

        m_ng1con_u: m_ng1con_u {
            compatible = "zmk,behavior-macro";
            #binding-cells = <0>;
            wait-ms = <5>;
            tap-ms = <5>;
            bindings = <&kp S>, <&macro_tap>, <&tog_off 15>;

            // ures
        };

        m_ng1_v: m_ng1_v {
            compatible = "zmk,behavior-macro";
            #binding-cells = <0>;
            wait-ms = <5>;
            tap-ms = <5>;
            bindings = <&kp I &kp V &kp E>, <&macro_tap>, <&tog_on 15>;

            // ive
        };

        m_ng1con_v: m_ng1con_v {
            compatible = "zmk,behavior-macro";
            #binding-cells = <0>;
            wait-ms = <5>;
            tap-ms = <5>;
            bindings = <&kp L &kp Y>, <&macro_tap>, <&tog_off 15>;

            // ively
        };

        m_ng1_w: m_ng1_w {
            compatible = "zmk,behavior-macro";
            #binding-cells = <0>;
            wait-ms = <5>;
            tap-ms = <5>;
            bindings =
                <&kp W &kp I &kp T &kp H &kp SPACE>,
                <&macro_tap>,
                <&tog_on 15>;

            // with
        };

        m_ng1con_w: m_ng1con_w {
            compatible = "zmk,behavior-macro";
            #binding-cells = <0>;
            wait-ms = <5>;
            tap-ms = <5>;
            bindings = <&kp BACKSPACE &kp I &kp N>, <&macro_tap>, <&tog_off 15>;

            // within
        };

        m_ng1_y: m_ng1_y {
            compatible = "zmk,behavior-macro";
            #binding-cells = <0>;
            wait-ms = <5>;
            tap-ms = <5>;
            bindings = <&kp I &kp T &kp Y>, <&macro_tap>, <&tog_on 15>;

            // ity
        };

        m_ng1con_y: m_ng1con_y {
            compatible = "zmk,behavior-macro";
            #binding-cells = <0>;
            wait-ms = <5>;
            tap-ms = <5>;
            bindings =
                <&kp BSPC &kp I &kp E &kp S>,
                <&macro_tap>,
                <&tog_off 15>;

            // ities
        };

        m_ng1_z: m_ng1_z {
            compatible = "zmk,behavior-macro";
            #binding-cells = <0>;
            wait-ms = <5>;
            tap-ms = <5>;
            bindings = <&kp I &kp Z &kp E>, <&macro_tap>, <&tog_on 15>;

            // ize
        };

        m_ng1con_z: m_ng1con_z {
            compatible = "zmk,behavior-macro";
            #binding-cells = <0>;
            wait-ms = <5>;
            tap-ms = <5>;
            bindings =
                <&kp BSPC &kp A &kp T &kp I &kp O &kp N>,
                <&macro_tap>,
                <&tog_off 15>;

            // ization
        };

        /* =========================================================================
         * NGRAM2 (Layer 16) & NGRAM2_CON (Layer 17) - Hold Key Pos 80
         * ========================================================================= */

        m_ng2_a: m_ng2_a {
            compatible = "zmk,behavior-macro";
            #binding-cells = <0>;
            wait-ms = <5>;
            tap-ms = <5>;
            bindings = <&kp A &kp N &kp C &kp E>, <&macro_tap>, <&tog_on 17>;

            // ance
        };

        m_ng2con_a: m_ng2con_a {
            compatible = "zmk,behavior-macro";
            #binding-cells = <0>;
            wait-ms = <5>;
            tap-ms = <5>;
            bindings = <&kp S>, <&macro_tap>, <&tog_off 17>;

            // ances
        };

        m_ng2_c: m_ng2_c {
            compatible = "zmk,behavior-macro";
            #binding-cells = <0>;
            wait-ms = <5>;
            tap-ms = <5>;
            bindings = <&kp C &kp O &kp M>, <&macro_tap>, <&tog_on 17>;

            // com
        };

        m_ng2con_c: m_ng2con_c {
            compatible = "zmk,behavior-macro";
            #binding-cells = <0>;
            wait-ms = <5>;
            tap-ms = <5>;
            bindings = <&kp M>, <&macro_tap>, <&tog_off 17>;

            // comm
        };

        m_ng2_e: m_ng2_e {
            compatible = "zmk,behavior-macro";
            #binding-cells = <0>;
            wait-ms = <5>;
            tap-ms = <5>;
            bindings = <&kp E &kp N &kp C &kp E>, <&macro_tap>, <&tog_on 17>;

            // ence
        };

        m_ng2con_e: m_ng2con_e {
            compatible = "zmk,behavior-macro";
            #binding-cells = <0>;
            wait-ms = <5>;
            tap-ms = <5>;
            bindings = <&kp S>, <&macro_tap>, <&tog_off 17>;

            // ences
        };

        m_ng2_f: m_ng2_f {
            compatible = "zmk,behavior-macro";
            #binding-cells = <0>;
            wait-ms = <5>;
            tap-ms = <5>;
            bindings =
                <&kp F &kp R &kp O &kp M &kp SPACE>,
                <&macro_tap>,
                <&tog_on 17>;

            // "from "
        };

        m_ng2con_f: m_ng2con_f {
            compatible = "zmk,behavior-macro";
            #binding-cells = <0>;
            wait-ms = <5>;
            tap-ms = <5>;
            bindings = <&kp LPAR>, <&macro_tap>, <&tog_off 17>;

            // "from ("
        };

        m_ng2_g: m_ng2_g {
            compatible = "zmk,behavior-macro";
            #binding-cells = <0>;
            wait-ms = <5>;
            tap-ms = <5>;
            bindings = <&kp G &kp R &kp O &kp U &kp P &kp SPACE &kp B &kp Y &kp SPACE>; // "group by "
        };

        m_ng2_h: m_ng2_h {
            compatible = "zmk,behavior-macro";
            #binding-cells = <0>;
            wait-ms = <5>;
            tap-ms = <5>;
            bindings = <&kp H &kp A &kp V &kp I &kp N &kp G &kp SPACE>;    // "having "
        };

        m_ng2_i: m_ng2_i {
            compatible = "zmk,behavior-macro";
            #binding-cells = <0>;
            wait-ms = <5>;
            tap-ms = <5>;
            bindings = <&kp I &kp B &kp L &kp E>, <&macro_tap>, <&tog_on 17>;

            // ible
        };

        m_ng2con_i: m_ng2con_i {
            compatible = "zmk,behavior-macro";
            #binding-cells = <0>;
            wait-ms = <5>;
            tap-ms = <5>;
            bindings = <&kp BSPC &kp Y>, <&macro_tap>, <&tog_off 17>;

            // ibly
        };

        m_ng2_j: m_ng2_j {
            compatible = "zmk,behavior-macro";
            #binding-cells = <0>;
            wait-ms = <5>;
            tap-ms = <5>;
            bindings =
                <&kp J &kp O &kp I &kp N &kp SPACE>,
                <&macro_tap>,
                <&tog_on 17>;

            // "join "
        };

        m_ng2con_j: m_ng2con_j {
            compatible = "zmk,behavior-macro";
            #binding-cells = <0>;
            wait-ms = <5>;
            tap-ms = <5>;
            bindings = <&kp O &kp N &kp SPACE>, <&macro_tap>, <&tog_off 17>;

            // "join on "
        };

        m_ng2_l: m_ng2_l {
            compatible = "zmk,behavior-macro";
            #binding-cells = <0>;
            wait-ms = <5>;
            tap-ms = <5>;
            bindings =
                <&kp L &kp I &kp K &kp E &kp SPACE>,
                <&macro_tap>,
                <&tog_on 17>;

            // "like "
        };

        m_ng2con_l: m_ng2con_l {
            compatible = "zmk,behavior-macro";
            #binding-cells = <0>;
            wait-ms = <5>;
            tap-ms = <5>;
            bindings =
                <&kp SQT &kp PERCENT &kp SQT>,
                <&macro_tap>,
                <&tog_off 17>;

            // "like '%'"
        };

        m_ng2_m: m_ng2_m {
            compatible = "zmk,behavior-macro";
            #binding-cells = <0>;
            wait-ms = <5>;
            tap-ms = <5>;
            bindings = <&kp M &kp A &kp X &kp LPAR>, <&macro_tap>, <&tog_on 17>;

            // "max("
        };

        m_ng2con_m: m_ng2con_m {
            compatible = "zmk,behavior-macro";
            #binding-cells = <0>;
            wait-ms = <5>;
            tap-ms = <5>;
            bindings =
                <&kp BSPC &kp BSPC &kp BSPC &kp BSPC &kp M &kp I &kp N &kp LPAR>,
                <&macro_tap>,
                <&tog_off 17>;

            // "min("
        };

        m_ng2_n: m_ng2_n {
            compatible = "zmk,behavior-macro";
            #binding-cells = <0>;
            wait-ms = <5>;
            tap-ms = <5>;
            bindings = <&kp N &kp U &kp L &kp L>;                          // null
        };

        m_ng2_o: m_ng2_o {
            compatible = "zmk,behavior-macro";
            #binding-cells = <0>;
            wait-ms = <5>;
            tap-ms = <5>;
            bindings = <&kp O &kp R &kp D &kp E &kp R &kp SPACE &kp B &kp Y &kp SPACE>; // "order by "
        };

        m_ng2_p: m_ng2_p {
            compatible = "zmk,behavior-macro";
            #binding-cells = <0>;
            wait-ms = <5>;
            tap-ms = <5>;
            bindings = <&kp P &kp R &kp E>;                                // pre
        };

        m_ng2_r: m_ng2_r {
            compatible = "zmk,behavior-macro";
            #binding-cells = <0>;
            wait-ms = <5>;
            tap-ms = <5>;
            bindings = <&kp R &kp E &kp T &kp U &kp R &kp N &kp SPACE>;    // "return "
        };

        m_ng2_s: m_ng2_s {
            compatible = "zmk,behavior-macro";
            #binding-cells = <0>;
            wait-ms = <5>;
            tap-ms = <5>;
            bindings =
                <&kp S &kp E &kp L &kp E &kp C &kp T &kp SPACE>,
                <&macro_tap>,
                <&tog_on 17>;

            // "select "
        };

        m_ng2con_s: m_ng2con_s {
            compatible = "zmk,behavior-macro";
            #binding-cells = <0>;
            wait-ms = <5>;
            tap-ms = <5>;
            bindings =
                <&kp D &kp I &kp S &kp T &kp I &kp N &kp C &kp T &kp SPACE>,
                <&macro_tap>,
                <&tog_off 17>;

            // "select distinct "
        };

        m_ng2_t: m_ng2_t {
            compatible = "zmk,behavior-macro";
            #binding-cells = <0>;
            wait-ms = <5>;
            tap-ms = <5>;
            bindings = <&kp T &kp H &kp I &kp S &kp SPACE>;                // "then "
        };

        m_ng2_u: m_ng2_u {
            compatible = "zmk,behavior-macro";
            #binding-cells = <0>;
            wait-ms = <5>;
            tap-ms = <5>;
            bindings =
                <&kp U &kp N &kp D &kp E &kp R>,
                <&macro_tap>,
                <&tog_on 17>;

            // under
        };

        m_ng2con_u: m_ng2con_u {
            compatible = "zmk,behavior-macro";
            #binding-cells = <0>;
            wait-ms = <5>;
            tap-ms = <5>;
            bindings =
                <&kp S &kp T &kp A &kp N &kp D>,
                <&macro_tap>,
                <&tog_off 17>;

            // understand
        };

        m_ng2_v: m_ng2_v {
            compatible = "zmk,behavior-macro";
            #binding-cells = <0>;
            wait-ms = <5>;
            tap-ms = <5>;
            bindings = <&kp V &kp A &kp L &kp U &kp E &kp S &kp SPACE &kp LPAR>; // "values ("
        };

        m_ng2_w: m_ng2_w {
            compatible = "zmk,behavior-macro";
            #binding-cells = <0>;
            wait-ms = <5>;
            tap-ms = <5>;
            bindings =
                <&kp W &kp H &kp E &kp R &kp E &kp SPACE>,
                <&macro_tap>,
                <&tog_on 17>;

            // "where "
        };

        m_ng2con_w: m_ng2con_w {
            compatible = "zmk,behavior-macro";
            #binding-cells = <0>;
            wait-ms = <5>;
            tap-ms = <5>;
            bindings =
                <&kp BSPC &kp V &kp E &kp R &kp SPACE>,
                <&macro_tap>,
                <&tog_off 17>;

            // "wherever "
        };
    };

    combos {
        compatible = "zmk,combos";

        combo_new_sentence {
            bindings = <&sentence_end PERIOD>;
            key-positions = <43 44>;
            layers = <0 6 7 11 10>;
        };

        question_combo {
            bindings = <&sentence_end QUESTION>;
            key-positions = <44 45>;
            layers = <0 6 7 11 10>;
        };

        bang_combo {
            bindings = <&sentence_end EXCLAMATION>;
            key-positions = <45 46>;
            layers = <0 6 7 11 10>;
            timeout-ms = <40>;
            require-prior-idle-ms = <100>;
        };

        mouse_combo {
            bindings = <&rgb_layer_to_yellow 5>;
            key-positions = <73 54>;
            layers = <0 1 3 2 6 7 8 10 11>;
        };

        mouse_combo2 {
            bindings = <&mkp RCLK>;
            key-positions = <74 42>;
        };

        capslock_combo {
            bindings = <&kp CAPSLOCK>;
            key-positions = <48 71>;
        };

        magic_combo {
            bindings = <&kp F13>;
            key-positions = <70 75>;
        };

        mouse1_combo {
            bindings = <&mkp LCLK>;
            key-positions = <40 39>;
        };

        mouse2_combo {
            bindings = <&mkp MCLK>;
            key-positions = <39 38>;
            require-prior-idle-ms = <250>;
        };

        mouse3_combo {
            bindings = <&mkp RCLK>;
            key-positions = <38 37>;
            timeout-ms = <40>;
            require-prior-idle-ms = <500>;
        };

        to0_combo {
            bindings = <&unshift_to_0>;
            key-positions = <37 40>;
        };

        ough_combo {
            bindings = <&ough_macro>;
            key-positions = <31 33>;
            require-prior-idle-ms = <10>;
            timeout-ms = <30>;
        };

        tion_combo {
            bindings = <&tion_macro>;
            key-positions = <33 32>;
            timeout-ms = <30>;
            require-prior-idle-ms = <10>;
        };

        ing_combo {
            bindings = <&ing_macro>;
            key-positions = <32 31>;
            timeout-ms = <75>;
        };

        qu_combo {
            bindings = <&qu_macro>;
            key-positions = <31 44>;
            layers = <0 6 10 11>;
            timeout-ms = <75>;
        };

        mouse_off_combo {
            bindings = <&unshift_to_0>;
            key-positions = <73 54>;
            layers = <5>;
        };

        qu_sentence_start_combo {
            bindings = <&qu_macro_sentence_start>;
            key-positions = <31 44>;
            layers = <8>;
        };

        dummy_combo {
            bindings = <&none>;
            key-positions = <63 71 43 44 45 46 62>;
        };

        and_combo {
            bindings = <&and_macro>;
            key-positions = <43 40>;
            require-prior-idle-ms = <10>;
        };

        thanks_combo {
            bindings = <&thanks_macro>;
            key-positions = <43 29>;
        };
    };

    keymap {
        compatible = "zmk,keymap";

        default_layer {
            bindings = <
&kp F12              &bt BT_SEL 0  &bt BT_SEL 1     &kp F3             &kp LA(F4)                    &kp F5                           &rgb_ug RGB_TOG  &kp F7               &kp F8                        &kp F9       &kp F10          &kp F11
&kp GRAVE            &kp N1        &kp N2           &kp N3             &kp N4                        &kp N5                           &kp N6           &kp N7               &kp N8                        &kp N9       &kp N0           &kp BACKSLASH
&kp TAB              &the_macro    &kp W            &kp E              &kp R                         &kp T                            &kp Y            &kp U                &kp I                         &kp O        &kp SEMICOLON    &hyphen_emdash 0 MINUS
&ctrl_esc LCTRL ESC  &hml LGUI A   &hml LEFT_ALT S  &hml LEFT_SHIFT D  &hml LCTRL F                  &kp G                            &kp H            &hmr RCTRL J         &hmr LSHIFT K                 &hmr LALT L  &hmr LGUI P      &single_quote_ht 0 APOSTROPHE
&kp Q                &kp Z         &kp X            &kp C              &kp V                         &kp B                            &kp N            &kp M                &kp COMMA                     &dot 13 DOT  &kp FSLH         &double_quote_ht 0 DOUBLE_QUOTES
&win_left            &win_right    &mkp MCLK        &mkp LCLK          &trans                                                                          &trans               &kp UNDERSCORE                &kp EQUAL    &kp LC(LS(TAB))  &kp LC(TAB)
                                                                       &rgb_layer_tap_enter 3 ENTER  &shift_dance  &hyper_tapdance    &mkp MCLK        &mkp LCLK            &rgb_layer_tap_space 1 SPACE
                                                                       &mkp RCLK                     &kp DEL       &kp RALT           &kp BACKSLASH    &ng_lt 16 BACKSPACE  &ng_lt (14) LC(BACKSPACE)
            >;
        };

        nav_editing {
            bindings = <
&kp F12         &kp F1             &kp F2             &kp F3                 &kp F4          &kp F5                         &kp F6         &kp F7             &kp F8           &kp F9               &kp F10      &kp F11
&to 4           &trans             &trans             &trans                 &kp END         &kp LC(A)                      &kp HOME       &trans             &trans           &trans               &kp HOME     &error
&trans          &select_word_left  &kp LC(RIGHT)      &select_word_right     &alt_tab_mm     &kp LC(UP)                     &error         &select_line_down  &select_line_up  &open_line           &error       &select_line_down
&trans          &hml LCMD HOME     &hml LALT PAGE_UP  &hml LSHIFT PAGE_DOWN  &hml LCTRL END  &kp LC(DOWN)                   &kp LEFT       &hmr RCTRL DOWN    &hmr LSHIFT UP   &hmr LEFT_ALT RIGHT  &paste_line  &trans
&kt LEFT_SHIFT  &error             &cut_line          &del_line              &to 2           &kp LC(LEFT)                   &tog_on 1      &kp C_VOL_DN       &kp C_VOL_UP     &kp DOT              &error       &trans
&trans          &trans             &trans             &trans                 &trans                                                        &trans             &trans           &trans               &trans       &trans
                                                                             &trans          &trans        &trans           &trans         &trans             &unshift_to_0
                                                                             &trans          &trans        &unshift_to_0    &unshift_to_0  &trans             &trans
            >;
        };

        nav_selecting {
            bindings = <
&surround GRAVE GRAVE  &trans                &trans                   &trans                       &trans                  &trans                                            &trans         &trans                 &trans                &trans                     &trans          &trans
&to 4                  &trans                &trans                   &trans                       &kp LS(END)             &kp LS(LC(A))                                     &kp LS(HOME)   &trans                 &trans                &trans                     &kp LS(HOME)    &error
&trans                 &kp LS(LC(LEFT))      &kp LS(LC(RIGHT))        &kp LS(LC(RIGHT))            &error                  &kp LS(LC(UP))                                    &error         &kp LS(DOWN)           &kp LS(UP)            &error                     &error          &select_line_down
&trans                 &hml (LCMD) LS(HOME)  &hml (LALT) LS(PAGE_UP)  &hml (LSHIFT) LS(PAGE_DOWN)  &hml (LCTRL) LS(END)    &kp LS(LC(DOWN))                                  &kp LS(LEFT)   &hmr (RCTRL) LS(DOWN)  &hmr (LSHIFT) LS(UP)  &hmr (LEFT_ALT) LS(RIGHT)  &paste_replace  &surround SQT SQT
&kt LEFT_SHIFT         &kp LC(Z)             &cancel_layer_kp LC(X)   &cancel_layer_kp LC(C)       &cancel_layer_kp LC(V)  &kp LS(LC(LEFT))                                  &tog 2         &kp C_VOL_DN           &kp C_VOL_UP          &kp C_MUTE                 &error          &surround DOUBLE_QUOTES DOUBLE_QUOTES
&trans                 &trans                &trans                   &trans                       &trans                                                                                   &trans                 &trans                &trans                     &trans          &trans
                                                                                                   &trans                  &cancel_layer_kp DEL  &cancel_layer_kp LC(DEL)    &trans         &trans                 &trans
                                                                                                   &trans                  &tog 2                &unshift_to_0               &unshift_to_0  &trans                 &trans
            >;
        };

        Numpad_symbol {
            bindings = <
&trans           &trans            &trans                          &trans                         &trans                   &trans                          &trans        &trans         &trans          &trans            &trans        &trans
&error           &kp EXCLAMATION   &kp AT                          &kp HASH                       &kp DOLLAR               &kp PERCENT                     &kp CARET     &kp AMPS       &kp STAR        &kp LPAR          &kp RPAR      &trans
&kp EXCLAMATION  &kp CARET         &kp LEFT_BRACKET                &kp RIGHT_BRACKET              &kp DOLLAR               &kp TILDE                       &kp ASTERISK  &kp N7         &kp N8          &kp N9            &kp COLON     &hyphen_endash 0 MINUS
&kp GRAVE        &hml LEFT_GUI LT  &hml LEFT_ALT LEFT_PARENTHESIS  &hml LSHIFT RIGHT_PARENTHESIS  &hml LCTRL GREATER_THAN  &kp EQUAL                       &kp PLUS      &hmr LCTRL N4  &hmr LSHIFT N5  &hmr LEFT_ALT N6  &hmr LGUI N0  &trans
&kp QUESTION     &kp AMPERSAND     &kp LEFT_BRACE                  &kp RIGHT_BRACE                &kp PERCENT              &tog_on 3                       &terminal     &kp NUMBER_1   &kp N2          &kp N3            &trans        &trans
&trans           &trans            &trans                          &trans                         &none                                                                  &none          &trans          &kp DOT           &trans        &unshift_to_0
                                                                                                  &trans                   &trans         &unshift_to_0    &trans        &trans         &kp SPACE
                                                                                                  &trans                   &unshift_to_0  &trans           &trans        &trans         &trans
            >;
        };

        Keyboard_Control_Layer {
            bindings = <
&trans       &trans        &trans        &trans        &trans        &trans                         &trans           &trans           &trans           &trans           &trans           &trans
&bt BT_CLR   &bt BT_SEL 0  &bt BT_SEL 1  &bt BT_SEL 2  &bt BT_SEL 3  &bt BT_SEL 4                   &trans           &rgb_ug RGB_TOG  &rgb_ug RGB_EFF  &trans           &trans           &trans
&sys_reset   &out OUT_TOG  &trans        &trans        &trans        &trans                         &rgb_ug RGB_TOG  &rgb_ug RGB_HUI  &rgb_ug RGB_SAI  &rgb_ug RGB_BRI  &rgb_ug RGB_SPI  &sys_reset
&bootloader  &trans        &trans        &trans        &trans        &trans                         &trans           &rgb_ug RGB_HUD  &rgb_ug RGB_SAD  &rgb_ug RGB_BRD  &rgb_ug RGB_SPD  &bootloader
&trans       &trans        &trans        &trans        &trans        &trans                         &trans           &trans           &trans           &trans           &trans           &trans
&trans       &trans        &trans        &trans        &trans                                                        &trans           &trans           &trans           &trans           &trans
                                                       &trans        &trans        &trans           &trans           &trans           &unshift_to_0
                                                       &trans        &trans        &unshift_to_0    &unshift_to_0    &trans           &trans
            >;
        };

        Mouse {
            bindings = <
&trans  &trans  &trans     &trans     &trans     &trans            &trans  &trans  &trans  &trans  &trans  &trans
&trans  &trans  &trans     &trans     &trans     &trans            &trans  &trans  &trans  &trans  &trans  &trans
&trans  &trans  &trans     &trans     &trans     &trans            &trans  &trans  &trans  &trans  &trans  &trans
&trans  &trans  &mkp RCLK  &mkp MCLK  &mkp LCLK  &trans            &trans  &trans  &trans  &trans  &trans  &trans
&trans  &trans  &trans     &trans     &trans     &trans            &trans  &trans  &trans  &trans  &trans  &trans
&trans  &trans  &trans     &trans     &trans                               &trans  &trans  &trans  &trans  &trans
                                      &trans     &trans  &trans    &trans  &trans  &trans
                                      &trans     &trans  &trans    &trans  &trans  &trans
            >;
        };

        caps_word {
            bindings = <
&cancel_layer_kp GRAVE  &cancel_layer_kp F1      &cancel_layer_kp F2     &cancel_layer_kp F3     &cancel_layer_kp F4           &cancel_layer_kp F5               &cancel_layer_kp F6     &cancel_layer_kp F7      &cancel_layer_kp F8           &cancel_layer_kp F9     &cancel_layer_kp F10           &cancel_layer_kp F11
&cancel_layer_kp EQUAL  &kp_unshifted N1         &kp_unshifted N2        &kp_unshifted N3        &kp_unshifted N4              &kp_unshifted N5                  &kp_unshifted N6        &kp_unshifted N7         &kp_unshifted N8              &kp_unshifted N9        &kp_unshifted N0               &cancel_layer_kp BACKSLASH
&cancel_layer_kp TAB    &trans                   &trans                  &trans                  &trans                        &trans                            &trans                  &trans                   &trans                        &trans                  &cancel_layer_kp SEMICOLON     &kp_unshifted MINUS
&ctrl_esc LCTRL ESCAPE  &trans                   &trans                  &trans                  &trans                        &trans                            &trans                  &trans                   &trans                        &trans                  &trans                         &cancel_layer_kp APOS
&trans                  &trans                   &trans                  &trans                  &trans                        &trans                            &trans                  &trans                   &cancel_layer_kp COMMA        &cancel_layer_kp DOT    &cancel_layer_kp FSLH          &cancel_layer_kp DOUBLE_QUOTES
&cancel_layer_win_left  &cancel_layer_win_right  &cancel_layer_mkp MCLK  &cancel_layer_mkp LCLK  &trans                                                                                  &trans                   &trans                        &cancel_layer_kp EQUAL  &cancel_layer_kp LS(LC(RALT))  &cancel_layer_kp LC(TAB)
                                                                                                 &rgb_layer_tap_enter 3 ENTER  &cancel_capsword_shift  &trans    &cancel_layer_mkp MCLK  &cancel_layer_mkp LCLK   &rgb_layer_tap_space 1 SPACE
                                                                                                 &cancel_layer_mkp RCLK        &trans                  &trans    &trans                  &kp_unshifted BACKSPACE  &kp_unshifted LC(BACKSPACE)
            >;
        };

        swap_trackballs {
            bindings = <
&trans  &trans  &trans  &trans  &trans  &trans            &trans  &trans  &trans  &trans  &trans  &trans
&trans  &trans  &trans  &trans  &trans  &trans            &trans  &trans  &trans  &trans  &trans  &trans
&trans  &trans  &trans  &trans  &trans  &trans            &trans  &trans  &trans  &trans  &trans  &trans
&trans  &trans  &trans  &trans  &trans  &trans            &trans  &trans  &trans  &trans  &trans  &trans
&trans  &trans  &trans  &trans  &trans  &trans            &trans  &trans  &trans  &trans  &trans  &trans
&trans  &trans  &trans  &trans  &trans                            &trans  &trans  &trans  &trans  &trans
                                &trans  &trans  &trans    &trans  &trans  &trans
                                &trans  &trans  &trans    &trans  &trans  &trans
            >;
        };

        new_sentence {
            bindings = <
&sentence_start_kp GRAVE      &bt BT_SEL 0                    &bt BT_SEL 1                        &bt BT_SEL 2                          &cancel_layer_kp LA(F4)          &cancel_layer_kp F5                  &rgb_ug RGB_TOG            &cancel_layer_kp F7              &cancel_layer_kp F8               &cancel_layer_kp F9             &cancel_layer_kp F10              &cancel_layer_kp F11
&sentence_start_kp LS(EQUAL)  &sentence_start_kp LS(N1)       &sentence_start_kp LS(N2)           &sentence_start_kp LS(N3)             &sentence_start_kp LS(N4)        &sentence_start_kp LS(N5)            &sentence_start_kp LS(N6)  &sentence_start_kp LS(N7)        &sentence_start_kp LS(N8)         &sentence_start_kp LS(N9)       &sentence_start_kp LS(N0)         &sentence_start_kp BACKSLASH
&cancel_layer_kp TAB          &sentence_start_the_macro       &sentence_start_kp LS(W)            &sentence_start_kp LS(E)              &sentence_start_kp LS(R)         &sentence_start_kp LS(T)             &sentence_start_kp LS(Y)   &sentence_start_kp LS(U)         &sentence_start_kp LS(I)          &sentence_start_kp LS(O)        &sentence_start_kp LS(SEMICOLON)  &sentence_start_kp MINUS
&ctrl_esc LCTRL ESCAPE        &hml_new_sentence (LGUI) LS(A)  &hml_new_sentence (LEFT_ALT) LS(S)  &hml_new_sentence (LEFT_SHIFT) LS(D)  &hml_new_sentence (LCTRL) LS(F)  &sentence_start_kp LS(G)             &sentence_start_kp LS(H)   &hmr_new_sentence (RCTRL) LS(J)  &hmr_new_sentence (LSHIFT) LS(K)  &hmr_new_sentence (LALT) LS(L)  &hmr_new_sentence (LGUI) LS(P)    &cancel_layer_kp SQT
&sentence_start_kp LS(Q)      &sentence_start_kp LS(Z)        &sentence_start_kp LS(X)            &sentence_start_kp LS(C)              &sentence_start_kp LS(V)         &sentence_start_kp LS(B)             &sentence_start_kp LS(N)   &sentence_start_kp LS(M)         &sentence_start_kp LS(COMMA)      &error_kp DOT                   &sentence_start_kp LS(FSLH)       &cancel_layer_kp DOUBLE_QUOTES
&cancel_layer_win_left        &cancel_layer_win_right         &cancel_layer_mkp MCLK              &cancel_layer_mkp LCLK                &trans                                                                                           &trans                           &sentence_start_kp UNDERSCORE     &sentence_start_kp EQUAL        &cancel_layer_kp LS(LC(TAB))      &cancel_layer_kp LC(TAB)
                                                                                                                                        &rgb_layer_tap_enter 3 ENTER     &cancel_capsword_shift     &trans    &cancel_layer_mkp MCLK     &cancel_layer_mkp LCLK           &rgb_layer_tap_space 1 SPACE
                                                                                                                                        &cancel_layer_mkp RCLK           &trans                     &trans    &mo_to_blue 1 1            &cancel_layer_kp BACKSPACE       &cancel_layer_kp LC(BACKSPACE)
            >;
        };

        Picture {
            bindings = <
&trans           &trans     &trans                &trans                 &trans         &trans                              &trans        &trans        &trans          &trans    &trans     &trans
&error           &error     &error                &error                 &none          &error                              &kp CARET     &kp AMPS      &kp STAR        &kp LPAR  &kp RPAR   &trans
&kp EXCLAMATION  &kp CARET  &kp LEFT_BRACKET      &kp RIGHT_BRACKET      &kp DOLLAR     &kp TILDE                           &kp ASTERISK  &kp N7        &kp N8          &kp N9    &kp COLON  &kp MINUS
&kp GRAVE        &kp LT     &kp LEFT_PARENTHESIS  &kp RIGHT_PARENTHESIS  &kp GT         &kp EQUAL                           &kp PLUS      &kp NUMBER_4  &kp N5          &kp N6    &kp N0     &kp SINGLE_QUOTE
&kp QUESTION     &kp STAR   &kp LEFT_BRACE        &kp RIGHT_BRACE        &kp SLASH      &kp DOUBLE_QUOTES                   &kp K_CALC    &kp NUMBER_1  &kp N2          &kp N3    &kp SLASH  &kp DOUBLE_QUOTES
&trans           &trans     &trans                &trans                 &none                                                            &none         &kp UNDERSCORE  &kp DOT   &trans     &trans
                                                                         &kp BACKSLASH  &unshift_to_0      &unshift_to_0    &trans        &trans        &trans
                                                                         &trans         &trans             &trans           &trans        &trans        &kp BACKSLASH
            >;
        };

        yes_trackballs {
            bindings = <
&trans  &trans  &trans  &trans  &trans  &trans            &trans  &trans  &trans  &trans  &trans  &trans
&trans  &trans  &trans  &trans  &trans  &trans            &trans  &trans  &trans  &trans  &trans  &trans
&trans  &trans  &trans  &trans  &trans  &trans            &trans  &trans  &trans  &trans  &trans  &trans
&trans  &trans  &trans  &trans  &trans  &trans            &trans  &trans  &trans  &trans  &trans  &trans
&trans  &trans  &trans  &trans  &trans  &trans            &trans  &trans  &trans  &trans  &trans  &trans
&trans  &trans  &trans  &trans  &trans                            &trans  &trans  &trans  &trans  &trans
                                &trans  &trans  &trans    &trans  &trans  &trans
                                &trans  &trans  &trans    &trans  &trans  &trans
            >;
        };

        no_trackballs {
            bindings = <
&trans  &trans  &trans  &trans  &trans  &trans            &trans  &trans  &trans  &trans  &trans  &trans
&trans  &trans  &trans  &trans  &trans  &trans            &trans  &trans  &trans  &trans  &trans  &trans
&trans  &trans  &trans  &trans  &trans  &trans            &trans  &trans  &trans  &trans  &trans  &trans
&trans  &trans  &trans  &trans  &trans  &trans            &trans  &trans  &trans  &trans  &trans  &trans
&trans  &trans  &trans  &trans  &trans  &trans            &trans  &trans  &trans  &trans  &trans  &trans
&trans  &trans  &trans  &trans  &trans                            &trans  &trans  &trans  &trans  &trans
                                &trans  &trans  &trans    &trans  &trans  &trans
                                &trans  &trans  &trans    &trans  &trans  &trans
            >;
        };

        hyper_layer {
            bindings = <
&trans     &trans  &trans  &trans  &trans  &trans            &trans  &trans  &trans  &trans      &trans  &trans
&trans     &trans  &trans  &trans  &trans  &trans            &trans  &trans  &trans  &trans      &trans  &trans
&trans     &kp Q   &trans  &trans  &trans  &trans            &trans  &trans  &trans  &trans      &trans  &trans
&trans     &trans  &trans  &trans  &trans  &trans            &trans  &trans  &trans  &trans      &trans  &trans
&kp LS(Q)  &trans  &trans  &trans  &trans  &trans            &trans  &trans  &trans  &kp PERIOD  &trans  &trans
&trans     &trans  &trans  &trans  &trans                            &trans  &trans  &trans      &trans  &trans
                                   &trans  &trans  &trans    &trans  &trans  &trans
                                   &trans  &trans  &trans    &trans  &trans  &trans
            >;
        };

        dot_layer {
            bindings = <
&trans  &trans      &trans     &trans         &trans                &trans                             &trans    &trans       &trans  &trans    &trans  &trans
&trans  &trans      &trans     &trans         &trans                &trans                             &trans    &trans       &trans  &trans    &trans  &trans
&trans  &trans      &trans     &dot_edu       &trans                &trans                             &trans    &trans       &trans  &dot_org  &trans  &trans
&trans  &alopresto  &sltccedu  &adamlopresto  &alopresto_stlcc_edu  &adamlopresto_gmail_com            &trans    &trans       &trans  &trans    &trans  &trans
&trans  &trans      &trans     &dot_com       &trans                &trans                             &dot_net  &mystlccedu  &trans  &trans    &trans  &trans
&trans  &trans      &trans     &trans         &trans                                                             &trans       &trans  &trans    &trans  &trans
                                              &trans                &trans                   &trans    &trans    &trans       &trans
                                              &trans                &trans                   &trans    &trans    &trans       &trans
            >;
        };

        ngram1 {
            display-name = "NG1";
            bindings = <
&trans  &trans    &trans    &trans    &trans    &trans              &trans    &trans    &trans    &trans    &trans    &trans
&trans  &trans    &trans    &trans    &trans    &trans              &trans    &trans    &trans    &trans    &trans    &trans
&trans  &trans    &m_ng1_w  &m_ng1_e  &trans    &m_ng1_t            &m_ng1_y  &m_ng1_u  &m_ng1_i  &m_ng1_o  &trans    &trans
&trans  &m_ng1_a  &m_ng1_s  &m_ng1_d  &m_ng1_f  &m_ng1_g            &m_ng1_h  &trans    &trans    &m_ng1_l  &m_ng1_p  &trans
&trans  &m_ng1_z  &trans    &m_ng1_c  &m_ng1_v  &trans              &m_ng1_n  &m_ng1_m  &trans    &trans    &trans    &trans
&trans  &trans    &trans    &trans    &trans                                  &trans    &trans    &trans    &trans    &trans
                                      &trans    &trans    &trans    &trans    &trans    &trans
                                      &trans    &trans    &trans    &trans    &trans    &trans
            >;
        };

        ngram1_con {
            display-name = "NG1+";
            bindings = <
&trans  &trans       &trans       &trans       &trans       &trans                 &trans       &trans       &trans       &trans       &trans       &trans
&trans  &trans       &trans       &trans       &trans       &trans                 &trans       &trans       &trans       &trans       &trans       &trans
&trans  &trans       &m_ng1con_w  &m_ng1con_e  &trans       &m_ng1con_t            &m_ng1con_y  &m_ng1con_u  &m_ng1con_i  &m_ng1con_o  &trans       &trans
&trans  &m_ng1con_a  &m_ng1con_s  &m_ng1con_d  &m_ng1con_f  &m_ng1con_g            &m_ng1con_h  &trans       &trans       &m_ng1con_l  &m_ng1con_p  &trans
&trans  &m_ng1con_z  &trans       &m_ng1con_c  &m_ng1con_v  &trans                 &m_ng1con_n  &m_ng1con_m  &trans       &trans       &trans       &trans
&trans  &trans       &trans       &trans       &trans                                           &trans       &trans       &trans       &trans       &trans
                                               &trans       &trans       &trans    &trans       &trans       &trans
                                               &trans       &trans       &trans    &trans       &trans       &trans
            >;
        };

        ngram2 {
            display-name = "NG2";
            bindings = <
&trans  &trans    &trans    &trans    &trans    &trans              &trans    &trans    &trans    &trans    &trans    &trans
&trans  &trans    &trans    &trans    &trans    &trans              &trans    &trans    &trans    &trans    &trans    &trans
&trans  &trans    &m_ng2_w  &m_ng2_e  &m_ng2_r  &m_ng2_t            &trans    &m_ng2_u  &m_ng2_i  &m_ng2_o  &trans    &trans
&trans  &m_ng2_a  &m_ng2_s  &trans    &m_ng2_f  &m_ng2_g            &m_ng2_h  &m_ng2_j  &trans    &m_ng2_l  &m_ng2_p  &trans
&trans  &trans    &trans    &m_ng2_c  &m_ng2_v  &trans              &m_ng2_n  &m_ng2_m  &trans    &trans    &trans    &trans
&trans  &trans    &trans    &trans    &trans                                  &trans    &trans    &trans    &trans    &trans
                                      &trans    &trans    &trans    &trans    &trans    &trans
                                      &trans    &trans    &trans    &trans    &trans    &trans
            >;
        };

        ngram2_con {
            display-name = "NG2+";
            bindings = <
&trans  &trans       &trans       &trans       &trans       &trans            &trans  &trans       &trans       &trans       &trans  &trans
&trans  &trans       &trans       &trans       &trans       &trans            &trans  &trans       &trans       &trans       &trans  &trans
&trans  &trans       &m_ng2con_w  &m_ng2con_e  &trans       &trans            &trans  &m_ng2con_u  &m_ng2con_i  &trans       &trans  &trans
&trans  &m_ng2con_a  &m_ng2con_s  &trans       &m_ng2con_f  &trans            &trans  &m_ng2con_j  &trans       &m_ng2con_l  &trans  &trans
&trans  &trans       &trans       &m_ng2con_c  &trans       &trans            &trans  &m_ng2con_m  &trans       &trans       &trans  &trans
&trans  &trans       &trans       &trans       &trans                                 &trans       &trans       &trans       &trans  &trans
                                               &trans       &trans  &trans    &trans  &trans       &trans
                                               &trans       &trans  &trans    &trans  &trans       &trans
            >;
        };
    };
};

// right hand trackball configuration

&trackball_peripheral_listener {
    input-processors = <&zip_auto_mouse 10 150>, <&zip_xy_scaler 0 1>;

    //     input-processors = <&zip_xy_scaler 2 3>;
    /*
    ignore_right {
        layers = <11>;
        input-processors = <&zip_xy_scaler 0 1>;
    };
    */

    arrows {
        layers = <3>;
        input-processors = <&zip_keybind_keys>;
        process-next;
    };

    arrows_prevent_movement {
        layers = <3>;
        input-processors = <&zip_xy_scaler 0 1>;
    };

    as_mouse {
        layers = <5 10>;
        input-processors = <&zip_xy_scaler 2 3>;
    };

    while_scrolling {
        layers = <11>;
        input-processors = <&zip_xy_scaler 0 1>;
    };

    // multiply sensitivity by 1, divide by 3 (make it slower for scrolling)
    // /* make this trackball output scrolling events by default instead of cursor movement */
    // /* invert vertical scrolling so that the view moves in the same direction as the top of the trackball */

    scroller {
        layers = <7>;
        input-processors =
            <&zip_xy_scaler 1 16>,
            <&zip_xy_to_scroll_mapper>,
            <&zip_scroll_transform INPUT_TRANSFORM_Y_INVERT>;
    };
};

//left hand trackball configuration

&trackball_central_listener {
    input-processors = <&zip_auto_mouse 11 500>, <&zip_xy_scaler 0 1>;

    /*   
    input-processors =
        // multiply sensitivity by 1, divide by 3 (make it slower for scrolling)
        <&zip_xy_scaler 1 16>,
            // make this trackball output scrolling events by default instead of cursor movement
            <&zip_xy_to_scroll_mapper>,
                // invert vertical scrolling so that the view moves in the same direction as the top of the trackball
                <&zip_scroll_transform INPUT_TRANSFORM_Y_INVERT>;
                */
    /*
                ignore_left {
                    layers = <11>;
                    input-processors = <&zip_xy_scaler 0 1>;
                };
                */

    as_scrollwheel {
        layers = <11>;
        input-processors =
            <&zip_x_scaler 0 16>,
            <&zip_y_scaler 1 16>,
            <&zip_xy_to_scroll_mapper>,
            <&zip_scroll_transform INPUT_TRANSFORM_Y_INVERT>;
    };

    volume_override {
        layers = <1>;
        input-processors = <&zip_scroll_to_vol>;
        process-next;
    };

    volume_override_prevent_movement {
        layers = <1>;
        input-processors = <&zip_xy_scaler 0 1>;
    };

    as_horiz_scrollwheel {
        layers = <2>;
        input-processors =
            <&zip_x_scaler 1 16>,
            <&zip_y_scaler 0 16>,
            <&zip_xy_to_scroll_mapper>,
            <&zip_scroll_transform INPUT_TRANSFORM_Y_INVERT>;
    };

    tracker {
        layers = <7>;
        input-processors = <&zip_xy_scaler 2 3>;
    };
};
